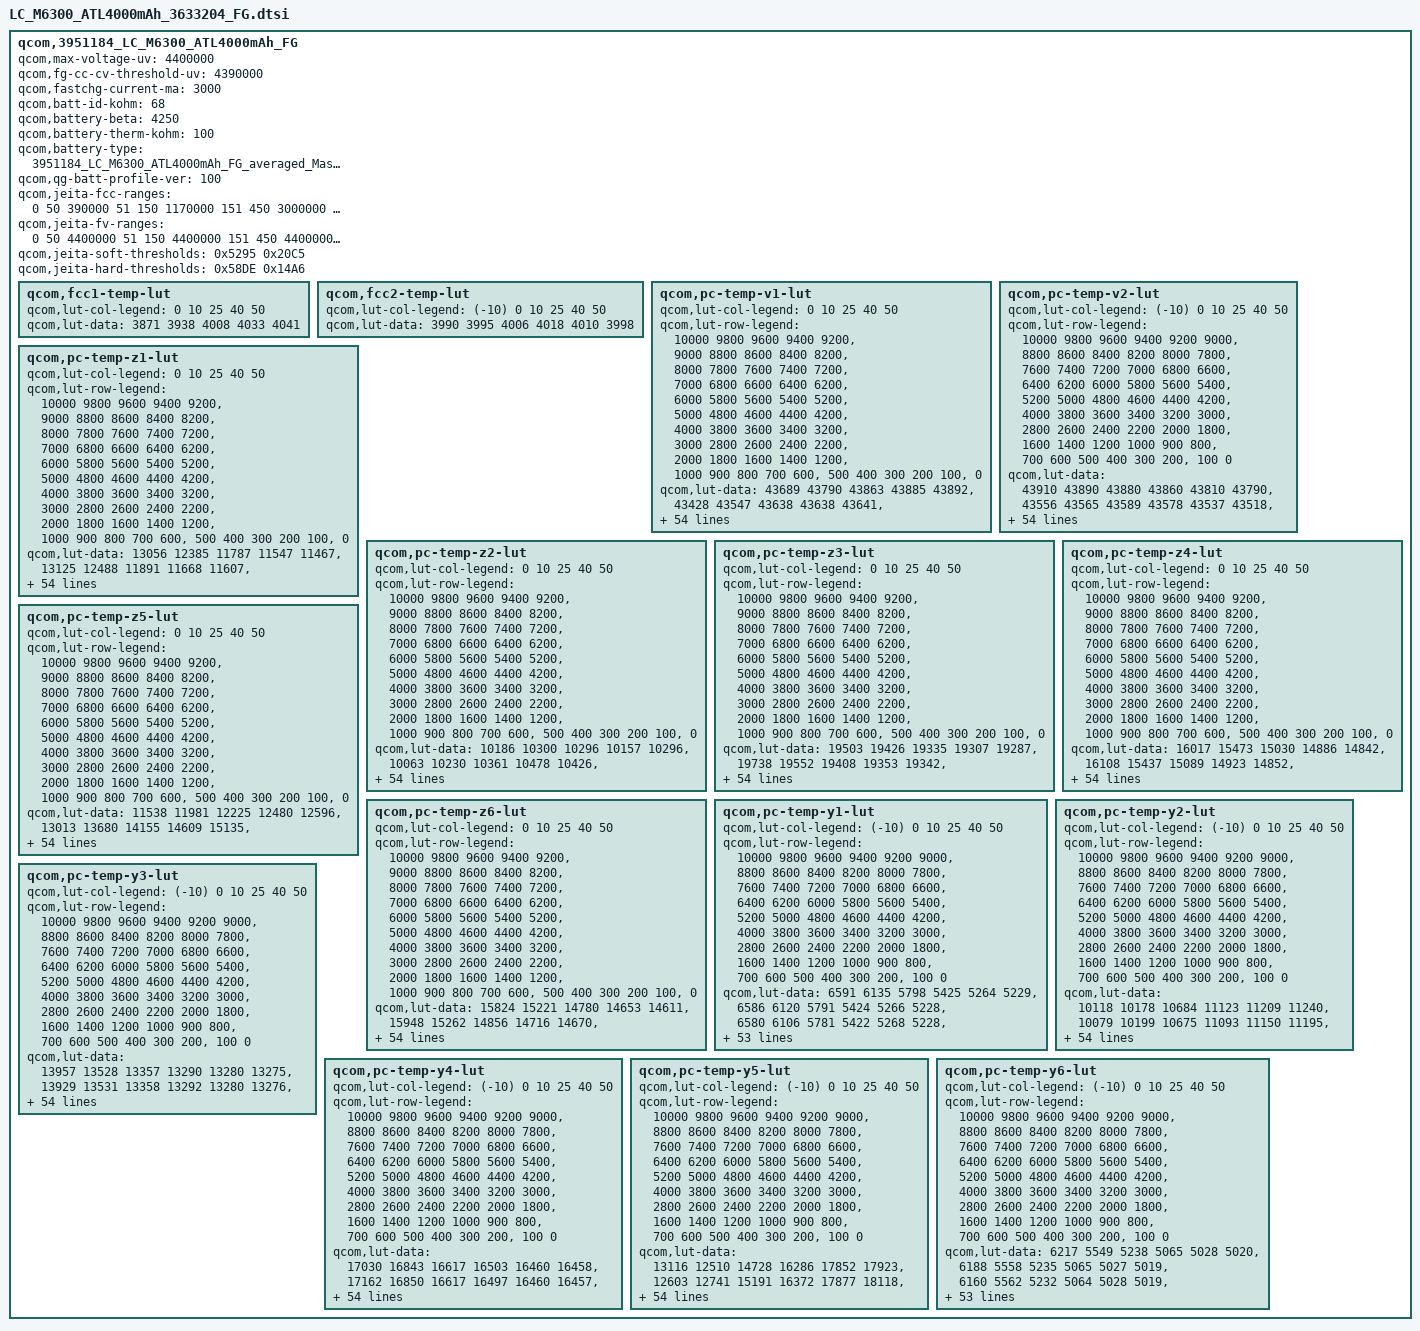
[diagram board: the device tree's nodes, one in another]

qcom,3951184_LC_M6300_ATL4000mAh_FG {
    /* 3951184_LC_M6300_ATL4000mAh_FG_averaged_MasterSlave_Apr3th2019 */
    qcom,max-voltage-uv = <4400000>;
    qcom,fg-cc-cv-threshold-uv = <4390000>;
    qcom,fastchg-current-ma = <3000>;
    qcom,batt-id-kohm = <68>;
    qcom,battery-beta = <4250>;
    qcom,battery-therm-kohm = <100>;
    qcom,battery-type = "3951184_LC_M6300_ATL4000mAh_FG_averaged_MasterSlave_Apr3th2019";
    qcom,qg-batt-profile-ver = <100>;

	qcom,jeita-fcc-ranges = <0   50  390000
				51  150   1170000
				151 450  3000000
				451 600  1950000>;
	qcom,jeita-fv-ranges = <0   50  4400000
				51  150  4400000
				151 450  4400000
				451 600  4100000>;

	/* COOL = 5 DegC, WARM = 45 DegC */
	qcom,jeita-soft-thresholds = <0x5295 0x20C5>;
	/* COLD = 0 DegC, HOT = 60 DegC */
	qcom,jeita-hard-thresholds = <0x58DE 0x14A6>;

	qcom,fcc1-temp-lut {
		qcom,lut-col-legend = <0 10 25 40 50>;
		qcom,lut-data = <3871 3938 4008 4033 4041>;
	};

	qcom,fcc2-temp-lut {
		qcom,lut-col-legend = <(-10) 0 10 25 40 50>;
		qcom,lut-data = <3990 3995 4006 4018 4010 3998>;
	};

	qcom,pc-temp-v1-lut {
		qcom,lut-col-legend = <0 10 25 40 50>;
		qcom,lut-row-legend = <10000 9800 9600 9400 9200>,
			<9000 8800 8600 8400 8200>,
			<8000 7800 7600 7400 7200>,
			<7000 6800 6600 6400 6200>,
			<6000 5800 5600 5400 5200>,
			<5000 4800 4600 4400 4200>,
			<4000 3800 3600 3400 3200>,
			<3000 2800 2600 2400 2200>,
			<2000 1800 1600 1400 1200>,
			<1000 900 800 700 600>,
			<500 400 300 200 100>,
			<0>;
		qcom,lut-data = <43689 43790 43863 43885 43892>,
			<43428 43547 43638 43638 43641>,
			<43180 43305 43394 43407 43412>,
			<42940 43064 43154 43177 43185>,
			<42703 42825 42915 42943 42954>,
			<42469 42589 42677 42707 42721>,
			<42240 42355 42441 42473 42490>,
			<42018 42126 42206 42240 42258>,
			<41801 41901 41978 42009 42029>,
			<41591 41682 41755 41779 41804>,
			<41385 41467 41535 41553 41580>,
			<41186 41258 41318 41333 41359>,
			<40994 41055 41103 41117 41139>,
			<40810 40867 40896 40909 40927>,
			<40607 40681 40694 40705 40723>,
			<40351 40472 40495 40508 40527>,
			<40097 40234 40290 40314 40335>,
			<39919 40025 40091 40125 40149>,
			<39785 39876 39920 39949 39972>,
			<39660 39747 39786 39800 39815>,
			<39530 39598 39636 39645 39654>,
			<39400 39431 39410 39432 39452>,
			<39252 39251 39145 39173 39211>,
			<39073 39028 38952 38973 39013>,
			<38897 38794 38808 38834 38864>,
			<38741 38659 38691 38718 38737>,
			<38597 38588 38597 38612 38620>,
			<38498 38528 38517 38517 38514>,
			<38436 38463 38439 38426 38418>,
			<38388 38401 38364 38335 38327>,
			<38341 38344 38295 38253 38245>,
			<38299 38292 38230 38183 38172>,
			<38261 38244 38170 38122 38105>,
			<38228 38202 38119 38066 38043>,
			<38199 38165 38078 38017 37989>,
			<38169 38128 38038 37969 37935>,
			<38144 38094 37997 37920 37874>,
			<38110 38056 37955 37869 37808>,
			<38055 37996 37895 37803 37732>,
			<37974 37908 37807 37715 37646>,
			<37881 37807 37706 37614 37548>,
			<37768 37695 37596 37504 37435>,
			<37635 37566 37470 37379 37306>,
			<37472 37410 37316 37221 37149>,
			<37331 37257 37168 37080 37014>,
			<37233 37163 37076 36990 36932>,
			<37200 37134 37050 36965 36905>,
			<37180 37114 37030 36950 36887>,
			<37167 37096 37014 36930 36866>,
			<37113 37053 36958 36860 36792>,
			<36883 36799 36692 36569 36493>,
			<36438 36365 36259 36127 36057>,
			<35864 35792 35686 35553 35489>,
			<35084 35009 34904 34767 34719>,
			<33853 33782 33682 33537 33531>,
			<30000 30000 30000 30000 30000>;
	};

	qcom,pc-temp-v2-lut {
		qcom,lut-col-legend = <(-10) 0 10 25 40 50>;
		qcom,lut-row-legend = <10000 9800 9600 9400 9200 9000>,
			<8800 8600 8400 8200 8000 7800>,
			<7600 7400 7200 7000 6800 6600>,
			<6400 6200 6000 5800 5600 5400>,
			<5200 5000 4800 4600 4400 4200>,
			<4000 3800 3600 3400 3200 3000>,
			<2800 2600 2400 2200 2000 1800>,
			<1600 1400 1200 1000 900 800>,
			<700 600 500 400 300 200>,
			<100 0>;
		qcom,lut-data = <43910 43890 43880 43860 43810 43790>,
			<43556 43565 43589 43578 43537 43518>,
			<43229 43262 43313 43311 43276 43257>,
			<42930 42984 43052 43058 43027 43009>,
			<42654 42732 42808 42820 42791 42775>,
			<42402 42487 42568 42586 42558 42543>,
			<42181 42242 42329 42351 42323 42310>,
			<41974 42002 42094 42117 42090 42078>,
			<41742 41775 41864 41887 41861 41849>,
			<41477 41555 41639 41659 41634 41623>,
			<41249 41345 41420 41435 41410 41400>,
			<41101 41145 41211 41213 41190 41181>,
			<40971 40952 41008 40995 40972 40966>,
			<40765 40760 40805 40790 40767 40760>,
			<40433 40577 40603 40593 40570 40558>,
			<40097 40366 40398 40396 40376 40363>,
			<39805 40058 40188 40185 40176 40176>,
			<39539 39719 39974 39979 39981 39996>,
			<39335 39491 39759 39805 39808 39823>,
			<39178 39335 39538 39657 39659 39663>,
			<39031 39186 39329 39488 39491 39489>,
			<38875 39013 39130 39252 39261 39265>,
			<38722 38843 38946 39005 39017 39028>,
			<38574 38702 38787 38825 38833 38845>,
			<38423 38585 38647 38679 38686 38695>,
			<38300 38468 38521 38553 38559 38566>,
			<38217 38325 38408 38441 38447 38453>,
			<38151 38184 38305 38340 38348 38353>,
			<38090 38089 38213 38248 38257 38260>,
			<38035 38021 38129 38165 38173 38173>,
			<37983 37967 38051 38087 38097 38094>,
			<37935 37924 37970 38013 38029 38024>,
			<37888 37887 37897 37944 37964 37958>,
			<37840 37849 37844 37883 37898 37889>,
			<37793 37812 37805 37829 37830 37820>,
			<37744 37772 37767 37772 37754 37739>,
			<37691 37728 37729 37706 37658 37628>,
			<37635 37680 37688 37636 37555 37503>,
			<37569 37623 37634 37563 37469 37405>,
			<37494 37557 37563 37486 37393 37327>,
			<37413 37480 37481 37401 37312 37246>,
			<37322 37384 37380 37304 37218 37152>,
			<37229 37269 37262 37193 37111 37048>,
			<37147 37136 37122 37058 36979 36917>,
			<37066 37006 36992 36934 36870 36809>,
			<36985 36914 36911 36888 36827 36767>,
			<36937 36878 36889 36870 36812 36751>,
			<36886 36845 36867 36849 36794 36736>,
			<36820 36800 36829 36808 36759 36701>,
			<36697 36712 36732 36686 36635 36588>,
			<36420 36464 36453 36354 36279 36222>,
			<35968 36005 35943 35844 35768 35729>,
			<35333 35370 35279 35186 35112 35082>,
			<34419 34478 34377 34254 34199 34209>,
			<32951 33031 33020 33004 32811 32899>,
			<28324 28078 28020 28126 28005 29135>;
	};

	qcom,pc-temp-z1-lut {
		qcom,lut-col-legend = <0 10 25 40 50>;
		qcom,lut-row-legend = <10000 9800 9600 9400 9200>,
			<9000 8800 8600 8400 8200>,
			<8000 7800 7600 7400 7200>,
			<7000 6800 6600 6400 6200>,
			<6000 5800 5600 5400 5200>,
			<5000 4800 4600 4400 4200>,
			<4000 3800 3600 3400 3200>,
			<3000 2800 2600 2400 2200>,
			<2000 1800 1600 1400 1200>,
			<1000 900 800 700 600>,
			<500 400 300 200 100>,
			<0>;
		qcom,lut-data = <13056 12385 11787 11547 11467>,
			<13125 12488 11891 11668 11607>,
			<13144 12524 11932 11693 11634>,
			<13155 12523 11938 11700 11644>,
			<13156 12521 11933 11701 11647>,
			<13153 12509 11927 11702 11648>,
			<13149 12478 11923 11702 11650>,
			<13143 12462 11918 11701 11654>,
			<13134 12462 11915 11701 11656>,
			<13131 12461 11913 11703 11656>,
			<13133 12460 11912 11705 11656>,
			<13134 12454 11912 11705 11657>,
			<13126 12447 11912 11704 11657>,
			<13098 12438 11911 11704 11658>,
			<13069 12427 11907 11704 11658>,
			<13037 12419 11905 11704 11659>,
			<13011 12411 11905 11704 11660>,
			<13010 12407 11905 11705 11661>,
			<13022 12409 11905 11706 11663>,
			<13029 12413 11908 11707 11665>,
			<13028 12418 11911 11708 11667>,
			<13025 12422 11913 11709 11667>,
			<13027 12427 11914 11710 11666>,
			<13050 12435 11916 11711 11665>,
			<13071 12445 11920 11713 11667>,
			<13074 12451 11924 11716 11670>,
			<13075 12455 11928 11719 11673>,
			<13075 12457 11932 11722 11677>,
			<13069 12458 11937 11726 11680>,
			<13063 12459 11943 11729 11684>,
			<13070 12460 11950 11733 11687>,
			<13098 12463 11955 11737 11690>,
			<13113 12466 11960 11741 11693>,
			<13108 12472 11965 11744 11696>,
			<13101 12479 11969 11746 11698>,
			<13101 12485 11974 11748 11700>,
			<13106 12492 11979 11751 11703>,
			<13113 12498 11985 11754 11705>,
			<13120 12502 11991 11757 11708>,
			<13127 12505 11995 11761 11710>,
			<13130 12509 12000 11764 11712>,
			<13130 12522 12005 11768 11713>,
			<13133 12529 12010 11772 11715>,
			<13154 12525 12014 11774 11719>,
			<13154 12538 12024 11778 11720>,
			<13155 12549 12030 11780 11719>,
			<13140 12545 12027 11780 11722>,
			<13112 12553 12024 11781 11722>,
			<13148 12542 12035 11783 11722>,
			<13168 12548 12034 11785 11726>,
			<13162 12553 12038 11791 11730>,
			<13177 12584 12054 11797 11736>,
			<13223 12606 12067 11807 11744>,
			<13227 12650 12088 11820 11756>,
			<13227 12650 12088 11820 11756>,
			<13227 12650 12088 11820 11756>;
	};

	qcom,pc-temp-z2-lut {
		qcom,lut-col-legend = <0 10 25 40 50>;
		qcom,lut-row-legend = <10000 9800 9600 9400 9200>,
			<9000 8800 8600 8400 8200>,
			<8000 7800 7600 7400 7200>,
			<7000 6800 6600 6400 6200>,
			<6000 5800 5600 5400 5200>,
			<5000 4800 4600 4400 4200>,
			<4000 3800 3600 3400 3200>,
			<3000 2800 2600 2400 2200>,
			<2000 1800 1600 1400 1200>,
			<1000 900 800 700 600>,
			<500 400 300 200 100>,
			<0>;
		qcom,lut-data = <10186 10300 10296 10157 10296>,
			<10063 10230 10361 10478 10426>,
			<10053 10191 10392 10378 10528>,
			<10049 10174 10398 10322 10582>,
			<10042 10162 10393 10408 10613>,
			<10034 10148 10385 10523 10633>,
			<10028 10134 10373 10528 10629>,
			<10023 10122 10358 10488 10588>,
			<10019 10113 10354 10467 10528>,
			<10018 10106 10353 10481 10408>,
			<10017 10107 10353 10498 10281>,
			<10017 10111 10367 10488 10264>,
			<10028 10119 10395 10450 10277>,
			<10060 10141 10405 10432 10296>,
			<10075 10174 10407 10432 10340>,
			<10046 10197 10408 10432 10390>,
			<10009 10214 10404 10413 10407>,
			<10012 10232 10395 10355 10414>,
			<10052 10260 10395 10330 10424>,
			<10091 10290 10413 10354 10444>,
			<10112 10302 10441 10400 10467>,
			<10128 10307 10483 10493 10485>,
			<10137 10311 10532 10645 10500>,
			<10142 10318 10537 10693 10524>,
			<10148 10325 10488 10576 10582>,
			<10158 10326 10451 10460 10653>,
			<10170 10324 10462 10462 10716>,
			<10176 10323 10488 10491 10777>,
			<10177 10326 10515 10524 10789>,
			<10178 10334 10546 10573 10667>,
			<10180 10338 10564 10608 10508>,
			<10186 10339 10555 10584 10407>,
			<10193 10339 10536 10527 10323>,
			<10206 10345 10523 10508 10304>,
			<10221 10359 10514 10507 10339>,
			<10232 10370 10509 10506 10394>,
			<10240 10376 10529 10549 10466>,
			<10248 10381 10568 10651 10551>,
			<10259 10393 10593 10719 10590>,
			<10272 10413 10608 10769 10607>,
			<10286 10424 10626 10794 10614>,
			<10298 10426 10665 10764 10613>,
			<10316 10428 10696 10724 10610>,
			<10352 10456 10680 10765 10579>,
			<10628 10600 10714 10727 10550>,
			<10690 10688 10741 10622 10577>,
			<10685 10683 10666 10594 10549>,
			<10686 10699 10667 10596 10512>,
			<10730 10784 10685 10647 10643>,
			<10845 10919 10783 10765 10785>,
			<10750 10804 10817 10628 10379>,
			<10552 10897 10887 10486 10297>,
			<10407 10862 10801 10399 10208>,
			<10196 10671 10736 10323 10145>,
			<10196 10671 10736 10323 10145>,
			<10196 10671 10736 10323 10145>;
	};

	qcom,pc-temp-z3-lut {
		qcom,lut-col-legend = <0 10 25 40 50>;
		qcom,lut-row-legend = <10000 9800 9600 9400 9200>,
			<9000 8800 8600 8400 8200>,
			<8000 7800 7600 7400 7200>,
			<7000 6800 6600 6400 6200>,
			<6000 5800 5600 5400 5200>,
			<5000 4800 4600 4400 4200>,
			<4000 3800 3600 3400 3200>,
			<3000 2800 2600 2400 2200>,
			<2000 1800 1600 1400 1200>,
			<1000 900 800 700 600>,
			<500 400 300 200 100>,
			<0>;
		qcom,lut-data = <19503 19426 19335 19307 19287>,
			<19738 19552 19408 19353 19342>,
			<19803 19613 19448 19371 19360>,
			<19838 19635 19466 19384 19372>,
			<19843 19645 19477 19398 19387>,
			<19843 19645 19482 19409 19398>,
			<19844 19639 19482 19410 19399>,
			<19838 19634 19482 19411 19398>,
			<19826 19631 19479 19411 19397>,
			<19819 19628 19461 19408 19386>,
			<19815 19624 19446 19402 19370>,
			<19813 19619 19445 19394 19365>,
			<19818 19612 19444 19381 19363>,
			<19835 19594 19442 19373 19360>,
			<19843 19574 19431 19372 19353>,
			<19830 19569 19422 19371 19346>,
			<19807 19568 19420 19368 19345>,
			<19778 19567 19419 19360 19344>,
			<19737 19550 19417 19354 19343>,
			<19709 19524 19413 19349 19338>,
			<19701 19522 19411 19345 19332>,
			<19696 19546 19420 19350 19333>,
			<19700 19569 19438 19365 19339>,
			<19739 19579 19441 19370 19341>,
			<19772 19586 19428 19352 19327>,
			<19773 19587 19414 19335 19311>,
			<19772 19576 19408 19334 19323>,
			<19771 19565 19403 19337 19360>,
			<19761 19562 19403 19344 19375>,
			<19748 19559 19415 19373 19375>,
			<19738 19559 19428 19398 19375>,
			<19730 19560 19438 19396 19373>,
			<19721 19561 19446 19388 19366>,
			<19711 19560 19446 19381 19359>,
			<19700 19555 19439 19375 19349>,
			<19691 19551 19431 19369 19343>,
			<19680 19548 19426 19365 19344>,
			<19672 19545 19422 19360 19344>,
			<19668 19541 19418 19359 19345>,
			<19666 19537 19413 19359 19343>,
			<19660 19533 19409 19358 19341>,
			<19644 19528 19407 19356 19344>,
			<19628 19520 19406 19353 19349>,
			<19615 19503 19396 19355 19350>,
			<19524 19476 19386 19350 19346>,
			<19489 19444 19372 19337 19323>,
			<19494 19445 19368 19337 19322>,
			<19465 19435 19370 19329 19321>,
			<19344 19406 19355 19325 19316>,
			<19344 19343 19344 19318 19312>,
			<19347 19422 19350 19334 19340>,
			<19336 19370 19328 19350 19346>,
			<19343 19343 19334 19342 19350>,
			<19339 19342 19332 19347 19344>,
			<19339 19342 19332 19347 19344>,
			<19339 19342 19332 19347 19344>;
	};

	qcom,pc-temp-z4-lut {
		qcom,lut-col-legend = <0 10 25 40 50>;
		qcom,lut-row-legend = <10000 9800 9600 9400 9200>,
			<9000 8800 8600 8400 8200>,
			<8000 7800 7600 7400 7200>,
			<7000 6800 6600 6400 6200>,
			<6000 5800 5600 5400 5200>,
			<5000 4800 4600 4400 4200>,
			<4000 3800 3600 3400 3200>,
			<3000 2800 2600 2400 2200>,
			<2000 1800 1600 1400 1200>,
			<1000 900 800 700 600>,
			<500 400 300 200 100>,
			<0>;
		qcom,lut-data = <16017 15473 15030 14886 14842>,
			<16108 15437 15089 14923 14852>,
			<15969 15375 15061 14916 14849>,
			<15719 15259 15025 14905 14845>,
			<15543 15131 14970 14877 14826>,
			<15406 15052 14916 14839 14795>,
			<15296 14991 14876 14812 14772>,
			<15212 14942 14843 14790 14752>,
			<15144 14901 14819 14771 14741>,
			<15087 14866 14802 14753 14738>,
			<15042 14839 14787 14740 14736>,
			<14998 14816 14769 14737 14732>,
			<14935 14800 14753 14737 14724>,
			<14860 14790 14749 14735 14717>,
			<14829 14783 14748 14725 14711>,
			<14846 14780 14747 14712 14706>,
			<14868 14780 14741 14706 14698>,
			<14869 14779 14727 14701 14688>,
			<14860 14774 14713 14697 14682>,
			<14847 14764 14696 14691 14679>,
			<14831 14755 14685 14687 14678>,
			<14814 14745 14717 14707 14694>,
			<14806 14739 14784 14770 14753>,
			<14802 14779 14824 14812 14795>,
			<14801 14856 14851 14836 14820>,
			<14816 14877 14864 14850 14834>,
			<14853 14863 14859 14845 14817>,
			<14868 14845 14847 14826 14764>,
			<14861 14830 14830 14800 14728>,
			<14850 14815 14801 14754 14712>,
			<14840 14800 14772 14715 14701>,
			<14830 14784 14748 14705 14693>,
			<14819 14770 14727 14699 14687>,
			<14808 14760 14718 14696 14685>,
			<14798 14751 14713 14694 14685>,
			<14789 14744 14710 14693 14685>,
			<14781 14738 14710 14695 14687>,
			<14775 14733 14711 14700 14693>,
			<14769 14735 14714 14706 14699>,
			<14764 14741 14728 14714 14705>,
			<14763 14744 14737 14719 14709>,
			<14769 14738 14728 14715 14701>,
			<14771 14734 14718 14707 14689>,
			<14760 14735 14722 14705 14689>,
			<14756 14714 14709 14698 14686>,
			<14760 14711 14697 14689 14685>,
			<14748 14703 14690 14678 14676>,
			<14775 14702 14673 14666 14658>,
			<14899 14724 14674 14650 14641>,
			<14891 14791 14685 14659 14643>,
			<14893 14717 14708 14675 14650>,
			<14922 14783 14739 14663 14647>,
			<14924 14816 14734 14673 14645>,
			<14943 14825 14738 14669 14652>,
			<14943 14825 14738 14669 14652>,
			<14943 14825 14738 14669 14652>;
	};

	qcom,pc-temp-z5-lut {
		qcom,lut-col-legend = <0 10 25 40 50>;
		qcom,lut-row-legend = <10000 9800 9600 9400 9200>,
			<9000 8800 8600 8400 8200>,
			<8000 7800 7600 7400 7200>,
			<7000 6800 6600 6400 6200>,
			<6000 5800 5600 5400 5200>,
			<5000 4800 4600 4400 4200>,
			<4000 3800 3600 3400 3200>,
			<3000 2800 2600 2400 2200>,
			<2000 1800 1600 1400 1200>,
			<1000 900 800 700 600>,
			<500 400 300 200 100>,
			<0>;
		qcom,lut-data = <11538 11981 12225 12480 12596>,
			<13013 13680 14155 14609 15135>,
			<13552 14798 15350 15398 16273>,
			<13893 15470 16116 16069 17251>,
			<14205 15968 16615 16882 18561>,
			<14479 16372 17051 17597 19769>,
			<14725 16688 17645 18044 20386>,
			<14935 17073 18220 18340 20783>,
			<15130 17633 18318 18688 20937>,
			<15401 18281 17980 19340 19967>,
			<15793 18986 17707 19906 18575>,
			<16341 19809 18306 19670 18464>,
			<17417 20185 19497 18663 18950>,
			<19147 20114 19711 18206 19215>,
			<19969 20013 18876 18935 18905>,
			<20052 20043 18220 19771 18503>,
			<20095 20283 18566 19757 18843>,
			<19834 20443 19542 19482 20318>,
			<18634 20024 20766 19379 21156>,
			<17849 19336 22554 19840 21248>,
			<18242 20420 25229 20777 21322>,
			<19375 28684 32342 23231 21740>,
			<22465 36062 41889 27799 22715>,
			<35296 38237 42859 29127 22970>,
			<45822 39598 33249 23304 19107>,
			<45921 39216 24361 17138 14938>,
			<44885 33242 21228 15985 15269>,
			<43320 27550 19199 15448 17384>,
			<39343 26183 18930 15606 19364>,
			<34870 25398 19778 19465 21048>,
			<32589 25283 21190 23825 22575>,
			<31074 26231 24675 25546 23890>,
			<29916 27494 29502 26686 25041>,
			<28982 28353 31498 27778 25622>,
			<28224 29103 32381 29040 25847>,
			<27567 29822 32746 29785 26066>,
			<26919 30671 32689 29430 26614>,
			<26580 31273 32509 28370 27336>,
			<27369 31197 31745 27046 27197>,
			<28925 30668 28392 24989 24125>,
			<29101 29930 25588 23110 21621>,
			<25994 28721 24923 21936 22449>,
			<24616 26964 24295 21207 23638>,
			<25539 23712 21614 21065 23357>,
			<22252 25628 22087 20475 21958>,
			<19476 22271 20652 18928 17295>,
			<20107 22313 20285 19564 17573>,
			<18023 21015 21704 19002 18895>,
			<12593 17209 18822 20271 21431>,
			<12673 13554 17289 17794 18895>,
			<12816 18937 16158 16610 20870>,
			<12361 14142 13763 18650 21263>,
			<12305 13018 13855 16583 21605>,
			<12032 12760 13509 16664 18396>,
			<12032 12760 13509 16664 18396>,
			<12032 12760 13509 16664 18396>;
	};

	qcom,pc-temp-z6-lut {
		qcom,lut-col-legend = <0 10 25 40 50>;
		qcom,lut-row-legend = <10000 9800 9600 9400 9200>,
			<9000 8800 8600 8400 8200>,
			<8000 7800 7600 7400 7200>,
			<7000 6800 6600 6400 6200>,
			<6000 5800 5600 5400 5200>,
			<5000 4800 4600 4400 4200>,
			<4000 3800 3600 3400 3200>,
			<3000 2800 2600 2400 2200>,
			<2000 1800 1600 1400 1200>,
			<1000 900 800 700 600>,
			<500 400 300 200 100>,
			<0>;
		qcom,lut-data = <15824 15221 14780 14653 14611>,
			<15948 15262 14856 14716 14670>,
			<15890 15270 14870 14728 14685>,
			<15783 15225 14870 14731 14690>,
			<15695 15160 14851 14726 14688>,
			<15617 15116 14827 14716 14683>,
			<15548 15079 14811 14708 14678>,
			<15493 15049 14797 14699 14671>,
			<15446 15024 14781 14690 14663>,
			<15409 15004 14764 14681 14655>,
			<15381 14987 14750 14672 14646>,
			<15355 14972 14741 14665 14640>,
			<15325 14957 14735 14659 14636>,
			<15293 14939 14729 14653 14631>,
			<15273 14922 14724 14647 14625>,
			<15264 14917 14718 14641 14619>,
			<15257 14915 14712 14636 14614>,
			<15243 14912 14706 14630 14610>,
			<15219 14900 14699 14625 14606>,
			<15199 14884 14689 14619 14601>,
			<15189 14881 14684 14615 14598>,
			<15182 14888 14704 14628 14606>,
			<15182 14900 14743 14665 14636>,
			<15199 14927 14758 14680 14652>,
			<15219 14964 14763 14681 14654>,
			<15234 14973 14765 14681 14656>,
			<15249 14964 14761 14679 14655>,
			<15253 14952 14754 14672 14651>,
			<15247 14945 14748 14667 14647>,
			<15237 14939 14743 14663 14642>,
			<15229 14933 14738 14660 14636>,
			<15221 14929 14734 14655 14631>,
			<15214 14925 14730 14649 14626>,
			<15205 14920 14725 14644 14621>,
			<15197 14916 14720 14639 14615>,
			<15190 14913 14716 14636 14612>,
			<15183 14911 14714 14636 14613>,
			<15180 14909 14712 14636 14616>,
			<15180 14910 14713 14636 14618>,
			<15180 14913 14717 14640 14620>,
			<15180 14915 14719 14643 14621>,
			<15180 14913 14717 14640 14619>,
			<15179 14909 14712 14636 14617>,
			<15175 14906 14710 14636 14618>,
			<15137 14888 14701 14631 14614>,
			<15127 14875 14690 14620 14603>,
			<15124 14872 14684 14616 14598>,
			<15120 14868 14678 14607 14590>,
			<15112 14863 14671 14598 14580>,
			<15112 14862 14672 14599 14578>,
			<15123 14875 14686 14615 14598>,
			<15138 14882 14691 14620 14602>,
			<15154 14890 14695 14623 14605>,
			<15179 14906 14701 14626 14608>,
			<15179 14906 14701 14626 14608>,
			<15179 14906 14701 14626 14608>;
	};

	qcom,pc-temp-y1-lut {
		qcom,lut-col-legend = <(-10) 0 10 25 40 50>;
		qcom,lut-row-legend = <10000 9800 9600 9400 9200 9000>,
			<8800 8600 8400 8200 8000 7800>,
			<7600 7400 7200 7000 6800 6600>,
			<6400 6200 6000 5800 5600 5400>,
			<5200 5000 4800 4600 4400 4200>,
			<4000 3800 3600 3400 3200 3000>,
			<2800 2600 2400 2200 2000 1800>,
			<1600 1400 1200 1000 900 800>,
			<700 600 500 400 300 200>,
			<100 0>;
		qcom,lut-data = <6591 6135 5798 5425 5264 5229>,
			<6586 6120 5791 5424 5266 5228>,
			<6580 6106 5781 5422 5268 5228>,
			<6574 6095 5770 5419 5268 5228>,
			<6569 6088 5761 5415 5267 5227>,
			<6566 6085 5756 5411 5265 5227>,
			<6565 6089 5755 5405 5261 5226>,
			<6564 6094 5754 5399 5257 5225>,
			<6566 6094 5752 5395 5256 5225>,
			<6573 6086 5748 5393 5257 5225>,
			<6581 6081 5743 5391 5257 5225>,
			<6587 6083 5738 5390 5256 5224>,
			<6593 6087 5732 5389 5253 5223>,
			<6591 6092 5727 5388 5252 5223>,
			<6576 6099 5723 5386 5252 5222>,
			<6565 6104 5721 5385 5252 5222>,
			<6575 6101 5724 5386 5253 5223>,
			<6590 6098 5728 5387 5254 5223>,
			<6591 6099 5729 5387 5255 5224>,
			<6575 6105 5729 5387 5255 5224>,
			<6563 6110 5729 5387 5255 5225>,
			<6572 6106 5725 5388 5256 5225>,
			<6586 6100 5719 5389 5257 5225>,
			<6587 6099 5720 5391 5257 5226>,
			<6573 6100 5729 5396 5258 5228>,
			<6559 6101 5737 5400 5258 5229>,
			<6553 6101 5740 5402 5260 5231>,
			<6548 6102 5742 5405 5264 5232>,
			<6546 6102 5746 5409 5267 5233>,
			<6545 6102 5756 5414 5270 5234>,
			<6544 6102 5762 5419 5272 5235>,
			<6540 6106 5764 5425 5275 5237>,
			<6535 6112 5765 5430 5278 5239>,
			<6533 6112 5769 5434 5280 5241>,
			<6532 6102 5781 5439 5282 5244>,
			<6532 6096 5787 5443 5284 5246>,
			<6531 6101 5786 5447 5286 5249>,
			<6531 6108 5786 5450 5288 5251>,
			<6528 6109 5787 5455 5290 5253>,
			<6514 6107 5791 5460 5291 5254>,
			<6503 6104 5796 5464 5293 5255>,
			<6511 6099 5800 5467 5295 5255>,
			<6523 6094 5801 5470 5298 5255>,
			<6511 6099 5800 5477 5301 5258>,
			<6509 6099 5808 5484 5305 5261>,
			<6537 6091 5796 5489 5306 5262>,
			<6566 6104 5815 5491 5307 5263>,
			<6531 6102 5817 5497 5305 5263>,
			<6544 6105 5820 5499 5306 5261>,
			<6504 6078 5818 5497 5304 5265>,
			<6571 6076 5808 5504 5310 5271>,
			<6565 6128 5843 5520 5315 5268>,
			<6573 6160 5834 5538 5324 5274>,
			<6636 6161 5863 5560 5336 5284>,
			<6636 6161 5863 5560 5336 5284>,
			<6636 6161 5863 5560 5336 5284>;
	};

	qcom,pc-temp-y2-lut {
		qcom,lut-col-legend = <(-10) 0 10 25 40 50>;
		qcom,lut-row-legend = <10000 9800 9600 9400 9200 9000>,
			<8800 8600 8400 8200 8000 7800>,
			<7600 7400 7200 7000 6800 6600>,
			<6400 6200 6000 5800 5600 5400>,
			<5200 5000 4800 4600 4400 4200>,
			<4000 3800 3600 3400 3200 3000>,
			<2800 2600 2400 2200 2000 1800>,
			<1600 1400 1200 1000 900 800>,
			<700 600 500 400 300 200>,
			<100 0>;
		qcom,lut-data = <10118 10178 10684 11123 11209 11240>,
			<10079 10199 10675 11093 11150 11195>,
			<10064 10219 10664 11061 11078 11123>,
			<10068 10238 10653 11031 11008 11044>,
			<10084 10255 10645 11006 10955 10981>,
			<10107 10271 10642 10988 10935 10955>,
			<10139 10285 10643 10975 10945 10960>,
			<10186 10297 10645 10967 10961 10968>,
			<10270 10305 10648 10973 10963 10966>,
			<10440 10309 10654 11010 10957 10947>,
			<10541 10316 10660 11031 10953 10927>,
			<10499 10405 10664 10993 10985 10914>,
			<10431 10547 10670 10940 11039 10904>,
			<10436 10602 10699 10942 11063 10907>,
			<10561 10621 10802 10994 11073 10942>,
			<10703 10641 10881 11050 11088 10994>,
			<10832 10667 10904 11096 11121 11093>,
			<10945 10699 10919 11144 11177 11214>,
			<10860 10742 10933 11206 11274 11269>,
			<10230 10807 10945 11286 11458 11299>,
			<9772 10879 10959 11320 11557 11312>,
			<9745 10972 10978 11271 11398 11280>,
			<9731 11059 11002 11207 11172 11222>,
			<9715 11064 11033 11202 11143 11187>,
			<9696 11006 11076 11218 11180 11161>,
			<9684 10965 11117 11240 11213 11150>,
			<9679 10964 11158 11273 11227 11188>,
			<9676 10964 11191 11314 11241 11269>,
			<9673 10962 11198 11350 11279 11353>,
			<9671 10956 11200 11385 11367 11459>,
			<9669 10947 11201 11407 11439 11514>,
			<9668 10933 11201 11416 11472 11471>,
			<9668 10906 11202 11423 11500 11403>,
			<9667 10773 11198 11441 11546 11411>,
			<9666 10204 11181 11470 11612 11525>,
			<9664 9788 11162 11480 11641 11599>,
			<9663 9734 11145 11442 11555 11541>,
			<9663 9704 11126 11388 11420 11439>,
			<9662 9689 11099 11363 11340 11387>,
			<9662 9680 11058 11347 11281 11359>,
			<9661 9673 11013 11328 11243 11336>,
			<9661 9669 10964 11300 11220 11320>,
			<9660 9666 10912 11275 11211 11300>,
			<9660 9664 10862 11260 11235 11240>,
			<9659 9661 10775 11148 11223 11109>,
			<9659 9661 10685 11141 11119 10939>,
			<9659 9660 10670 11123 11109 10937>,
			<9658 9659 10619 11120 11044 10993>,
			<9658 9658 10586 11071 11091 10982>,
			<9658 9657 10551 11065 11062 11109>,
			<9657 9657 10486 11039 11003 10921>,
			<9656 9656 10292 10966 10927 10856>,
			<9655 9655 9730 10885 10905 10788>,
			<9653 9654 9683 10819 10858 10684>,
			<9653 9654 9683 10819 10858 10684>,
			<9653 9654 9683 10819 10858 10684>;
	};

	qcom,pc-temp-y3-lut {
		qcom,lut-col-legend = <(-10) 0 10 25 40 50>;
		qcom,lut-row-legend = <10000 9800 9600 9400 9200 9000>,
			<8800 8600 8400 8200 8000 7800>,
			<7600 7400 7200 7000 6800 6600>,
			<6400 6200 6000 5800 5600 5400>,
			<5200 5000 4800 4600 4400 4200>,
			<4000 3800 3600 3400 3200 3000>,
			<2800 2600 2400 2200 2000 1800>,
			<1600 1400 1200 1000 900 800>,
			<700 600 500 400 300 200>,
			<100 0>;
		qcom,lut-data = <13957 13528 13357 13290 13280 13275>,
			<13929 13531 13358 13292 13280 13276>,
			<13886 13532 13359 13293 13280 13276>,
			<13840 13532 13361 13295 13281 13277>,
			<13803 13531 13363 13296 13281 13278>,
			<13787 13529 13363 13297 13282 13279>,
			<13791 13522 13363 13298 13284 13280>,
			<13797 13511 13363 13300 13285 13282>,
			<13792 13513 13363 13301 13286 13283>,
			<13751 13532 13362 13302 13287 13283>,
			<13697 13545 13362 13302 13287 13284>,
			<13621 13508 13365 13302 13288 13285>,
			<13542 13449 13368 13301 13288 13286>,
			<13530 13439 13367 13302 13289 13286>,
			<13547 13453 13360 13305 13294 13286>,
			<13558 13461 13355 13307 13297 13286>,
			<13517 13453 13357 13305 13294 13288>,
			<13447 13437 13359 13301 13290 13291>,
			<13424 13425 13359 13302 13289 13291>,
			<13417 13416 13353 13306 13291 13289>,
			<13414 13405 13347 13308 13292 13287>,
			<13421 13390 13342 13304 13288 13283>,
			<13432 13374 13336 13298 13281 13279>,
			<13433 13366 13332 13295 13279 13277>,
			<13423 13362 13329 13294 13279 13276>,
			<13415 13358 13327 13293 13279 13275>,
			<13415 13355 13323 13292 13279 13276>,
			<13414 13351 13321 13291 13279 13277>,
			<13417 13346 13320 13291 13279 13277>,
			<13439 13336 13320 13293 13279 13276>,
			<13465 13330 13320 13293 13279 13275>,
			<13484 13333 13318 13292 13280 13275>,
			<13502 13339 13316 13291 13280 13275>,
			<13523 13346 13316 13291 13281 13275>,
			<13547 13353 13318 13293 13281 13277>,
			<13573 13361 13320 13294 13281 13279>,
			<13602 13372 13323 13294 13280 13277>,
			<13634 13385 13325 13294 13278 13275>,
			<13667 13398 13326 13294 13278 13275>,
			<13704 13410 13326 13292 13278 13276>,
			<13742 13426 13326 13292 13278 13277>,
			<13777 13454 13326 13292 13278 13278>,
			<13814 13493 13326 13292 13279 13279>,
			<13863 13545 13329 13293 13279 13278>,
			<13909 13610 13332 13293 13282 13277>,
			<13869 13600 13329 13296 13285 13283>,
			<13894 13641 13332 13298 13286 13282>,
			<13956 13712 13340 13302 13290 13286>,
			<14017 13782 13347 13308 13295 13289>,
			<14084 13857 13355 13309 13293 13288>,
			<14166 13921 13362 13307 13289 13285>,
			<14286 14012 13367 13312 13289 13286>,
			<14477 14135 13408 13320 13295 13287>,
			<14971 14274 13483 13328 13300 13294>,
			<14971 14274 13483 13328 13300 13294>,
			<14971 14274 13483 13328 13300 13294>;
	};

	qcom,pc-temp-y4-lut {
		qcom,lut-col-legend = <(-10) 0 10 25 40 50>;
		qcom,lut-row-legend = <10000 9800 9600 9400 9200 9000>,
			<8800 8600 8400 8200 8000 7800>,
			<7600 7400 7200 7000 6800 6600>,
			<6400 6200 6000 5800 5600 5400>,
			<5200 5000 4800 4600 4400 4200>,
			<4000 3800 3600 3400 3200 3000>,
			<2800 2600 2400 2200 2000 1800>,
			<1600 1400 1200 1000 900 800>,
			<700 600 500 400 300 200>,
			<100 0>;
		qcom,lut-data = <17030 16843 16617 16503 16460 16458>,
			<17162 16850 16617 16497 16460 16457>,
			<17242 16863 16617 16493 16460 16455>,
			<17284 16877 16617 16491 16460 16454>,
			<17299 16889 16617 16490 16460 16453>,
			<17301 16895 16617 16490 16460 16452>,
			<17246 16896 16616 16492 16461 16452>,
			<17157 16897 16616 16495 16462 16451>,
			<17134 16890 16617 16498 16464 16452>,
			<17130 16851 16626 16504 16468 16455>,
			<17129 16826 16635 16511 16474 16459>,
			<17263 16925 16640 16520 16480 16463>,
			<17481 17081 16645 16533 16486 16467>,
			<17480 17109 16667 16545 16490 16472>,
			<17206 17086 16735 16557 16493 16479>,
			<16997 17049 16774 16572 16498 16486>,
			<16960 16934 16766 16593 16510 16490>,
			<16940 16788 16746 16614 16529 16494>,
			<16937 16760 16717 16624 16549 16505>,
			<16942 16761 16660 16631 16573 16531>,
			<16945 16761 16612 16633 16584 16547>,
			<16905 16749 16581 16583 16553 16527>,
			<16828 16725 16559 16514 16503 16492>,
			<16783 16705 16549 16492 16481 16474>,
			<16752 16690 16543 16481 16469 16464>,
			<16737 16669 16541 16478 16464 16459>,
			<16745 16621 16543 16481 16466 16460>,
			<16759 16567 16546 16488 16471 16463>,
			<16760 16559 16546 16493 16476 16467>,
			<16751 16580 16543 16498 16486 16475>,
			<16745 16594 16539 16504 16495 16485>,
			<16745 16594 16532 16514 16507 16497>,
			<16747 16595 16525 16523 16517 16509>,
			<16750 16600 16525 16525 16518 16511>,
			<16754 16630 16532 16526 16517 16509>,
			<16759 16659 16541 16526 16515 16507>,
			<16762 16675 16549 16516 16496 16491>,
			<16765 16686 16558 16503 16473 16467>,
			<16764 16692 16564 16498 16470 16462>,
			<16756 16695 16569 16494 16472 16462>,
			<16746 16696 16571 16494 16474 16462>,
			<16740 16696 16572 16498 16476 16462>,
			<16736 16694 16572 16501 16477 16462>,
			<16741 16676 16569 16500 16470 16457>,
			<16758 16671 16564 16494 16458 16452>,
			<16747 16660 16555 16486 16460 16452>,
			<16756 16671 16568 16500 16472 16468>,
			<16776 16688 16585 16515 16491 16489>,
			<16799 16718 16609 16538 16511 16515>,
			<16807 16746 16631 16540 16514 16504>,
			<16789 16740 16629 16516 16470 16451>,
			<16777 16722 16624 16512 16470 16457>,
			<16785 16727 16684 16532 16477 16464>,
			<16934 16756 16747 16581 16510 16493>,
			<16934 16756 16747 16581 16510 16493>,
			<16934 16756 16747 16581 16510 16493>;
	};

	qcom,pc-temp-y5-lut {
		qcom,lut-col-legend = <(-10) 0 10 25 40 50>;
		qcom,lut-row-legend = <10000 9800 9600 9400 9200 9000>,
			<8800 8600 8400 8200 8000 7800>,
			<7600 7400 7200 7000 6800 6600>,
			<6400 6200 6000 5800 5600 5400>,
			<5200 5000 4800 4600 4400 4200>,
			<4000 3800 3600 3400 3200 3000>,
			<2800 2600 2400 2200 2000 1800>,
			<1600 1400 1200 1000 900 800>,
			<700 600 500 400 300 200>,
			<100 0>;
		qcom,lut-data = <13116 12510 14728 16286 17852 17923>,
			<12603 12741 15191 16372 17877 18118>,
			<12370 13167 15599 16410 17863 18360>,
			<12366 13648 15926 16410 17816 18605>,
			<12540 14041 16142 16381 17743 18809>,
			<12840 14205 16219 16333 17653 18927>,
			<14072 14186 16153 16206 17552 18981>,
			<15723 14156 16002 15990 17414 19013>,
			<15890 14436 15786 15732 17163 18931>,
			<15002 15968 15408 15386 16653 18408>,
			<14403 16975 15202 14985 16107 17804>,
			<14423 15440 15236 14414 15514 17321>,
			<14490 13014 15287 13880 15012 16830>,
			<15422 13354 15245 13734 15033 16250>,
			<20275 17842 14999 13679 15491 15508>,
			<23577 20830 14856 13661 15772 15126>,
			<20564 19690 17424 13755 15049 15350>,
			<15560 17858 21179 13995 13977 15703>,
			<14425 17533 21824 15112 13960 15690>,
			<14381 17795 21816 18597 14883 15223>,
			<14365 17971 21803 20729 15931 14911>,
			<14870 17829 21277 21147 17039 16056>,
			<15720 17600 20333 21367 17979 17875>,
			<15683 17992 19596 21159 18103 18222>,
			<14224 20442 18924 20183 18037 18113>,
			<12957 22105 18446 19237 17925 17947>,
			<12555 21270 18127 18410 17464 17682>,
			<12301 19464 17917 17805 16835 17279>,
			<12295 17607 18269 17937 16512 16696>,
			<12554 15267 19950 18621 16294 15725>,
			<12832 13999 20919 18943 16214 15172>,
			<12996 14542 19814 18562 16454 15152>,
			<13133 15434 18287 18110 16941 15143>,
			<13254 15491 18104 18622 17611 15528>,
			<13358 14722 18387 20472 18650 17579>,
			<13462 14168 18729 21324 19134 18916>,
			<13580 14126 19171 21286 18873 18754>,
			<13704 14105 19565 21197 18371 18463>,
			<13829 14139 19453 20619 17797 18309>,
			<13976 14358 18671 18928 17035 18210>,
			<14059 14509 17893 17606 16454 18167>,
			<13788 14298 17241 16790 16064 18266>,
			<13378 14032 16927 16386 15915 18430>,
			<13278 13998 17035 16251 16540 18584>,
			<13094 13704 17048 16360 17954 17637>,
			<13226 13611 15882 17318 17546 18916>,
			<13098 13403 15748 16289 16609 16715>,
			<13186 13599 16015 16006 16878 17288>,
			<13579 13594 16091 16390 18058 17013>,
			<14265 14023 16415 16940 17154 15439>,
			<13967 14153 17374 17283 17679 19275>,
			<13653 14026 16414 19977 17864 19497>,
			<13831 13924 14369 21290 21482 18821>,
			<13045 13846 14470 22166 24603 26373>,
			<13045 13846 14470 22166 24603 26373>,
			<13045 13846 14470 22166 24603 26373>;
	};

	qcom,pc-temp-y6-lut {
		qcom,lut-col-legend = <(-10) 0 10 25 40 50>;
		qcom,lut-row-legend = <10000 9800 9600 9400 9200 9000>,
			<8800 8600 8400 8200 8000 7800>,
			<7600 7400 7200 7000 6800 6600>,
			<6400 6200 6000 5800 5600 5400>,
			<5200 5000 4800 4600 4400 4200>,
			<4000 3800 3600 3400 3200 3000>,
			<2800 2600 2400 2200 2000 1800>,
			<1600 1400 1200 1000 900 800>,
			<700 600 500 400 300 200>,
			<100 0>;
		qcom,lut-data = <6217 5549 5238 5065 5028 5020>,
			<6188 5558 5235 5065 5027 5019>,
			<6160 5562 5232 5064 5028 5019>,
			<6134 5562 5229 5064 5028 5020>,
			<6110 5559 5226 5065 5028 5020>,
			<6089 5555 5223 5065 5029 5021>,
			<6071 5546 5220 5065 5030 5022>,
			<6055 5535 5217 5067 5032 5023>,
			<6032 5530 5216 5069 5033 5024>,
			<5998 5528 5216 5070 5035 5025>,
			<5980 5527 5215 5072 5036 5027>,
			<5982 5528 5216 5075 5038 5028>,
			<5985 5529 5218 5077 5040 5030>,
			<5978 5530 5223 5081 5043 5032>,
			<5932 5533 5235 5087 5046 5034>,
			<5883 5535 5241 5092 5050 5036>,
			<5848 5504 5240 5096 5052 5039>,
			<5820 5454 5237 5099 5054 5042>,
			<5809 5440 5229 5103 5058 5045>,
			<5805 5437 5209 5108 5066 5051>,
			<5802 5435 5190 5109 5070 5054>,
			<5796 5425 5177 5092 5058 5046>,
			<5790 5414 5168 5068 5039 5031>,
			<5786 5413 5163 5060 5031 5025>,
			<5781 5416 5161 5056 5027 5021>,
			<5779 5418 5160 5055 5026 5020>,
			<5789 5414 5160 5056 5026 5020>,
			<5810 5409 5161 5057 5028 5021>,
			<5830 5410 5162 5059 5030 5023>,
			<5850 5424 5165 5062 5033 5025>,
			<5871 5443 5166 5065 5036 5027>,
			<5891 5462 5167 5068 5040 5031>,
			<5912 5485 5167 5070 5044 5034>,
			<5934 5508 5169 5072 5044 5035>,
			<5959 5531 5177 5075 5044 5036>,
			<5986 5556 5187 5076 5044 5037>,
			<6013 5584 5196 5073 5038 5031>,
			<6043 5615 5206 5070 5031 5023>,
			<6071 5649 5216 5069 5030 5022>,
			<6100 5687 5226 5068 5031 5022>,
			<6129 5729 5237 5068 5032 5024>,
			<6158 5775 5250 5071 5033 5025>,
			<6191 5826 5265 5073 5034 5026>,
			<6232 5882 5286 5075 5032 5023>,
			<6278 5951 5310 5075 5031 5022>,
			<6255 5945 5298 5075 5035 5026>,
			<6279 5987 5321 5081 5039 5031>,
			<6332 6053 5352 5089 5047 5040>,
			<6394 6122 5384 5101 5056 5049>,
			<6452 6198 5420 5103 5056 5045>,
			<6522 6256 5451 5097 5040 5029>,
			<6627 6332 5489 5101 5041 5031>,
			<6803 6444 5583 5117 5049 5035>,
			<7315 6584 5716 5143 5064 5050>,
			<7315 6584 5716 5143 5064 5050>,
			<7315 6584 5716 5143 5064 5050>;
	};

};
